# TRI0_445.0.8 register map
Vendor: Texas Instruments
Peripheral module from a debugger description file (folder msp430).
Registers are 16-bit, read-write, no defined reset value unless marked. A register's access mark holds for its fields unless they carry their own. Offsets are as the file gives them; lines under a group give offsets from that group; [hi:lo] are bit positions; {n}, {i} and the like mark numbered series; 'fields as' and 'values as' point back to an identical list; <NAME> marks a mode.

## TRI0
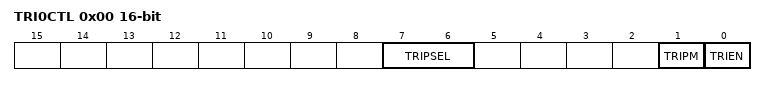
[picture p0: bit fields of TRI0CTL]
0x00 TRI0CTL — TRI Control Register
  [7:6] TRIPSEL — TRI positive input select.
    0=External source (package terminal); 1=Device specific; refer to the device-specific sheet for details; 2=Device specific; refer to the device-specific sheet for details; 3=Device specific; refer to the device-specific sheet for details
  [1] TRIPM — TRI power mode select.
    0=High speed and high power; 1=Low speed and low power
  [0] TRIEN — TRI enable.
    0=DISABLE (Disable the TRI module); 1=ENABLE (Enable the TRI module)
